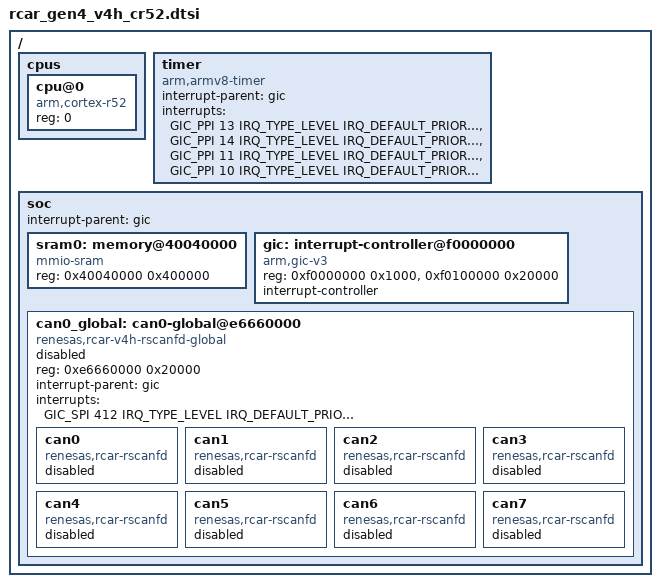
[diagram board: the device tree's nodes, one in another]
/*
 * Copyright (c) 2025 Renesas Electronics Corporation
 *
 * SPDX-License-Identifier: Apache-2.0
 */

#include <mem.h>
#include <arm64/armv8-r.dtsi>
#include <zephyr/dt-bindings/interrupt-controller/arm-gic.h>
#include <zephyr/dt-bindings/clock/renesas_cpg_mssr.h>

/ {
	cpus {
		#address-cells = <1>;
		#size-cells = <0>;

		cpu@0 {
			device_type = "cpu";
			compatible = "arm,cortex-r52";
			reg = <0>;
		};
	};

	timer {
		compatible = "arm,armv8-timer";
		interrupt-parent = <&gic>;
		interrupts = <GIC_PPI 13 IRQ_TYPE_LEVEL IRQ_DEFAULT_PRIORITY>,
			     <GIC_PPI 14 IRQ_TYPE_LEVEL IRQ_DEFAULT_PRIORITY>,
			     <GIC_PPI 11 IRQ_TYPE_LEVEL IRQ_DEFAULT_PRIORITY>,
			     <GIC_PPI 10 IRQ_TYPE_LEVEL IRQ_DEFAULT_PRIORITY>;
	};

	soc {
		interrupt-parent = <&gic>;

		sram0: memory@40040000 {
			compatible = "mmio-sram";
			reg = <0x40040000 0x400000>;
		};

		gic: interrupt-controller@f0000000 {
			compatible = "arm,gic-v3", "arm,gic";
			reg = <0xf0000000 0x1000>,
			      <0xf0100000 0x20000>;
			interrupt-controller;
			#interrupt-cells = <4>;
			status = "okay";
		};

		can0_global: can0-global@e6660000 {
			compatible = "renesas,rcar-v4h-rscanfd-global";
			reg = <0xe6660000 0x20000>;
			interrupt-parent = <&gic>;
			interrupts = <GIC_SPI 412 IRQ_TYPE_LEVEL IRQ_DEFAULT_PRIORITY>;
			status = "disabled";

			can0: can0 {
				compatible = "renesas,rcar-rscanfd";
				status = "disabled";
			};

			can1: can1 {
				compatible = "renesas,rcar-rscanfd";
				status = "disabled";
			};

			can2: can2 {
				compatible = "renesas,rcar-rscanfd";
				status = "disabled";
			};

			can3: can3 {
				compatible = "renesas,rcar-rscanfd";
				status = "disabled";
			};

			can4: can4 {
				compatible = "renesas,rcar-rscanfd";
				status = "disabled";
			};

			can5: can5 {
				compatible = "renesas,rcar-rscanfd";
				status = "disabled";
			};

			can6: can6 {
				compatible = "renesas,rcar-rscanfd";
				status = "disabled";
			};

			can7: can7 {
				compatible = "renesas,rcar-rscanfd";
				status = "disabled";
			};
		};
	};
};
